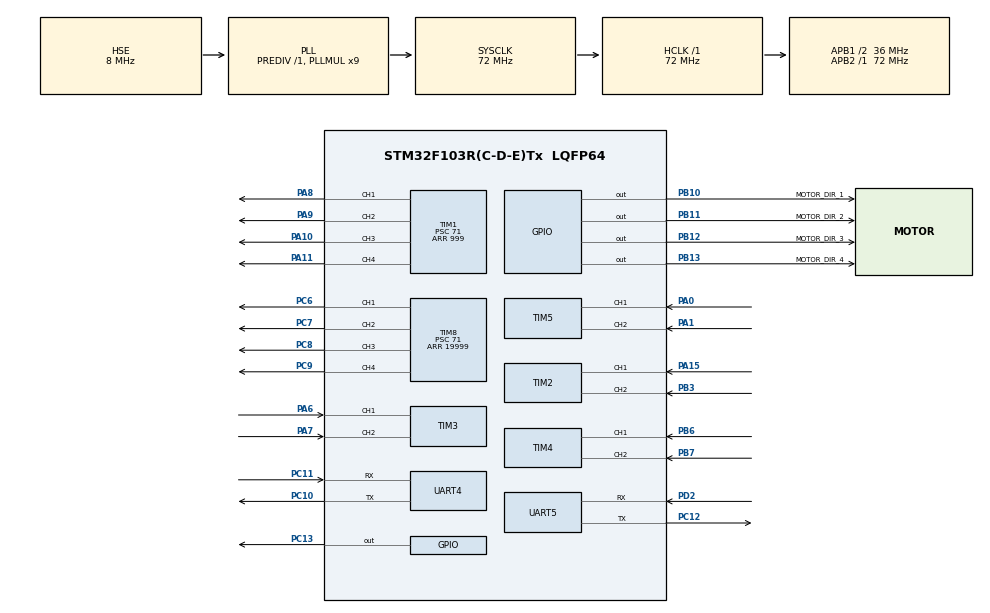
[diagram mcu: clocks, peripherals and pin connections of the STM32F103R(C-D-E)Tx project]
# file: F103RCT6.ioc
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Mcu.Family=STM32F1
Mcu.Name=STM32F103R(C-D-E)Tx
Mcu.Package=LQFP64
NVIC.PriorityGroup=NVIC_PRIORITYGROUP_2
NVIC.TIM6_IRQn=true\:3\:0\:true\:false\:true\:true\:true
NVIC.UART4_IRQn=true\:2\:0\:true\:false\:true\:true\:true
PA0-WKUP.Signal=S_TIM5_CH1
PA1.Signal=S_TIM5_CH2
PA10.Signal=S_TIM1_CH3
PA11.Signal=S_TIM1_CH4
PA13.Mode=Serial_Wire
PA13.Signal=SYS_JTMS-SWDIO
PA14.Mode=Serial_Wire
PA14.Signal=SYS_JTCK-SWCLK
PA15.Signal=S_TIM2_CH1_ETR
PA6.Signal=S_TIM3_CH1
PA7.Signal=S_TIM3_CH2
PA8.Signal=S_TIM1_CH1
PA9.Signal=S_TIM1_CH2
PB10.GPIO_Label=MOTOR_DIR_1
PB10.Signal=GPIO_Output
PB11.GPIO_Label=MOTOR_DIR_2
PB11.Signal=GPIO_Output
PB12.GPIO_Label=MOTOR_DIR_3
PB12.Signal=GPIO_Output
PB13.GPIO_Label=MOTOR_DIR_4
PB13.Signal=GPIO_Output
PB3.Signal=S_TIM2_CH2
PB6.Signal=S_TIM4_CH1
PB7.Signal=S_TIM4_CH2
PC10.Mode=Asynchronous
PC10.Signal=UART4_TX
PC11.Mode=Asynchronous
PC11.Signal=UART4_RX
PC12.Mode=Asynchronous
PC12.Signal=UART5_TX
PC13-TAMPER-RTC.Signal=GPIO_Output
PC14-OSC32_IN.Mode=LSE-External-Oscillator
PC14-OSC32_IN.Signal=RCC_OSC32_IN
PC15-OSC32_OUT.Mode=LSE-External-Oscillator
PC15-OSC32_OUT.Signal=RCC_OSC32_OUT
PC6.Signal=S_TIM8_CH1
PC7.Signal=S_TIM8_CH2
PC8.Signal=S_TIM8_CH3
PC9.Signal=S_TIM8_CH4
PD0-OSC_IN.Mode=HSE-External-Oscillator
PD0-OSC_IN.Signal=RCC_OSC_IN
PD1-OSC_OUT.Mode=HSE-External-Oscillator
PD1-OSC_OUT.Signal=RCC_OSC_OUT
PD2.Mode=Asynchronous
PD2.Signal=UART5_RX
ProjectManager.HeapSize=0x200
ProjectManager.StackSize=0x400
ProjectManager.TargetToolchain=MDK-ARM V5.32
RCC.AHBFreq_Value=72000000
RCC.APB1CLKDivider=RCC_HCLK_DIV2
RCC.APB1Freq_Value=36000000
RCC.APB1TimFreq_Value=72000000
RCC.APB2Freq_Value=72000000
RCC.APB2TimFreq_Value=72000000
RCC.HCLKFreq_Value=72000000
RCC.PLLMUL=RCC_PLL_MUL9
RCC.PLLSourceVirtual=RCC_PLLSOURCE_HSE
RCC.SYSCLKFreq_VALUE=72000000
RCC.SYSCLKSource=RCC_SYSCLKSOURCE_PLLCLK
RCC.USBFreq_Value=72000000
SH.S_TIM1_CH1.0=TIM1_CH1,PWM Generation1 CH1
SH.S_TIM1_CH2.0=TIM1_CH2,PWM Generation2 CH2
SH.S_TIM1_CH3.0=TIM1_CH3,PWM Generation3 CH3
SH.S_TIM1_CH4.0=TIM1_CH4,PWM Generation4 CH4
SH.S_TIM2_CH1_ETR.0=TIM2_CH1,Encoder_Interface
SH.S_TIM2_CH2.0=TIM2_CH2,Encoder_Interface
SH.S_TIM3_CH1.0=TIM3_CH1,Encoder_Interface
SH.S_TIM3_CH2.0=TIM3_CH2,Encoder_Interface
SH.S_TIM4_CH1.0=TIM4_CH1,Encoder_Interface
SH.S_TIM4_CH2.0=TIM4_CH2,Encoder_Interface
SH.S_TIM5_CH1.0=TIM5_CH1,Encoder_Interface
SH.S_TIM5_CH2.0=TIM5_CH2,Encoder_Interface
SH.S_TIM8_CH1.0=TIM8_CH1,PWM Generation1 CH1
SH.S_TIM8_CH2.0=TIM8_CH2,PWM Generation2 CH2
SH.S_TIM8_CH3.0=TIM8_CH3,PWM Generation3 CH3
SH.S_TIM8_CH4.0=TIM8_CH4,PWM Generation4 CH4
TIM1.AutoReloadPreload=TIM_AUTORELOAD_PRELOAD_ENABLE
TIM1.Channel-PWM\ Generation1\ CH1=TIM_CHANNEL_1
TIM1.Channel-PWM\ Generation2\ CH2=TIM_CHANNEL_2
TIM1.Channel-PWM\ Generation3\ CH3=TIM_CHANNEL_3
TIM1.Channel-PWM\ Generation4\ CH4=TIM_CHANNEL_4
TIM1.Period=999
TIM1.Prescaler=71
TIM1.Pulse-PWM\ Generation1\ CH1=300
TIM1.Pulse-PWM\ Generation2\ CH2=300
TIM1.Pulse-PWM\ Generation3\ CH3=300
TIM1.Pulse-PWM\ Generation4\ CH4=300
TIM6.Period=99
TIM6.Prescaler=35
TIM8.Channel-PWM\ Generation1\ CH1=TIM_CHANNEL_1
TIM8.Channel-PWM\ Generation2\ CH2=TIM_CHANNEL_2
TIM8.Channel-PWM\ Generation3\ CH3=TIM_CHANNEL_3
TIM8.Channel-PWM\ Generation4\ CH4=TIM_CHANNEL_4
TIM8.Period=19999
TIM8.Prescaler=71
UART4.VirtualMode=Asynchronous
UART5.VirtualMode=Asynchronous
VP_TIM6_VS_ClockSourceINT.Mode=Enable_Timer
board=custom

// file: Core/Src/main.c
/* USER CODE BEGIN Header */
/**
  ******************************************************************************
  * @file           : main.c
  * @brief          : Main program body
  ******************************************************************************
  * @attention
  *
  * <h2><center>&copy; Copyright (c) 2021 STMicroelectronics.
  * All rights reserved.</center></h2>
  *
  * This software component is licensed by ST under BSD 3-Clause license,
  * the "License"; You may not use this file except in compliance with the
  * License. You may obtain a copy of the License at:
  *                        opensource.org/licenses/BSD-3-Clause
  *
  ******************************************************************************
  */
/* USER CODE END Header */
#include "main.h"
#include "tim.h"
#include "usart.h"
#include "gpio.h"

/* USER CODE BEGIN Includes */
#include "uart_drv.h"
#include "string.h"
/* USER CODE END Includes */

void SystemClock_Config(void);

int main(void)
{

  /* MCU Configuration--------------------------------------------------------*/

  /* Reset of all peripherals, Initializes the Flash interface and the Systick. */
  HAL_Init();

  /* Configure the system clock */
  SystemClock_Config();

  /* Initialize all configured peripherals */
  MX_GPIO_Init();
  MX_TIM1_Init();
  MX_TIM2_Init();
  MX_TIM3_Init();
  MX_TIM4_Init();
  MX_TIM5_Init();
  MX_TIM8_Init();
  MX_UART4_Init();
  MX_UART5_Init();
  MX_TIM6_Init();

  /* Infinite loop */
  while (1)
  {

    /* USER CODE BEGIN 3 */
		HAL_Delay(500);
  }
  /* USER CODE END 3 */
}

void SystemClock_Config(void)
{
  RCC_OscInitTypeDef RCC_OscInitStruct = {0};
  RCC_ClkInitTypeDef RCC_ClkInitStruct = {0};

  /** Initializes the RCC Oscillators according to the specified parameters
  * in the RCC_OscInitTypeDef structure.
  */
  RCC_OscInitStruct.OscillatorType = RCC_OSCILLATORTYPE_HSE;
  RCC_OscInitStruct.HSEState = RCC_HSE_ON;
  RCC_OscInitStruct.HSEPredivValue = RCC_HSE_PREDIV_DIV1;
  RCC_OscInitStruct.HSIState = RCC_HSI_ON;
  RCC_OscInitStruct.PLL.PLLState = RCC_PLL_ON;
  RCC_OscInitStruct.PLL.PLLSource = RCC_PLLSOURCE_HSE;
  RCC_OscInitStruct.PLL.PLLMUL = RCC_PLL_MUL9;
  if (HAL_RCC_OscConfig(&RCC_OscInitStruct) != HAL_OK)
  {
    Error_Handler();
  }
  /** Initializes the CPU, AHB and APB buses clocks
  */
  RCC_ClkInitStruct.ClockType = RCC_CLOCKTYPE_HCLK|RCC_CLOCKTYPE_SYSCLK
                              |RCC_CLOCKTYPE_PCLK1|RCC_CLOCKTYPE_PCLK2;
  RCC_ClkInitStruct.SYSCLKSource = RCC_SYSCLKSOURCE_PLLCLK;
  RCC_ClkInitStruct.AHBCLKDivider = RCC_SYSCLK_DIV1;
  RCC_ClkInitStruct.APB1CLKDivider = RCC_HCLK_DIV2;
  RCC_ClkInitStruct.APB2CLKDivider = RCC_HCLK_DIV1;

  if (HAL_RCC_ClockConfig(&RCC_ClkInitStruct, FLASH_LATENCY_2) != HAL_OK)
  {
    Error_Handler();
  }
}

void Error_Handler(void)
{
  __disable_irq();
  while (1)
  {
  }
}

/************************ (C) COPYRIGHT STMicroelectronics *****END OF FILE****/
